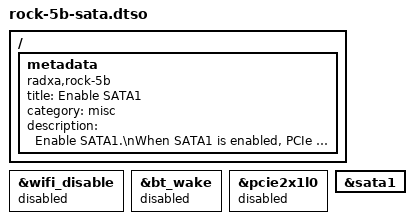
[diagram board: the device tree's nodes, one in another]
// ROCK 5B Pcie M.2 to sata
/dts-v1/;
/plugin/;

/ {
	metadata {
		title = "Enable SATA1";
		compatible = "radxa,rock-5b";
		category = "misc";
		description = "Enable SATA1.\nWhen SATA1 is enabled, PCIe cannot be enabled on the same port.";
	};

	fragment@0 {
		target = <&wifi_disable>;

		__overlay__ {
			status = "disabled";
		};
	};

	fragment@1 {
		target = <&bt_wake>;

		__overlay__ {
			status = "disabled";
		};
	};

	fragment@2 {
		target = <&pcie2x1l0>;

		__overlay__ {
			status = "disabled";
		};
	};

	fragment@3 {
		target = <&sata1>;

		__overlay__ {
			status = "okay";
		};
	};
};
